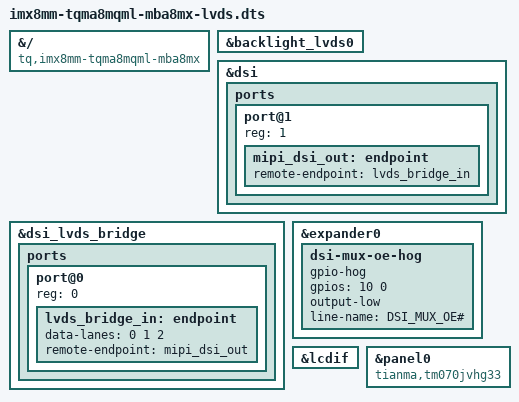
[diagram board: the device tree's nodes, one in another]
// SPDX-License-Identifier: (GPL-2.0-or-later OR MIT)
/*
 * Copyright 2021-2022 TQ-Systems GmbH
 */

/dts-v1/;
/plugin/;

&{/} {
	compatible = "tq,imx8mm-tqma8mqml-mba8mx", "tq,imx8mm-tqma8mqml", "fsl,imx8mm";
};

&backlight_lvds0 {
	status = "okay";
};

&dsi {
	status = "okay";

	ports {
		#address-cells = <1>;
		#size-cells = <0>;

		port@1 {
			reg = <1>;

			mipi_dsi_out: endpoint {
				remote-endpoint = <&lvds_bridge_in>;
			};
		};
	};
};

&dsi_lvds_bridge {
	status = "okay";

	ports {
		#address-cells = <1>;
		#size-cells = <0>;

		port@0 {
			reg = <0>;

			lvds_bridge_in: endpoint {
				// data-lanes = <0 1 2 3>; /* does NOT work */
				data-lanes = <0 1 2>; /* does work */
				remote-endpoint = <&mipi_dsi_out>;
			};
		};
	};
};

&expander0 {
	dsi-mux-oe-hog {
		gpio-hog;
		gpios = <10 0>;
		output-low;
		line-name = "DSI_MUX_OE#";
	};
};

&lcdif {
	status = "okay";
};

&panel0 {
	compatible = "tianma,tm070jvhg33";
	status = "okay";
};
